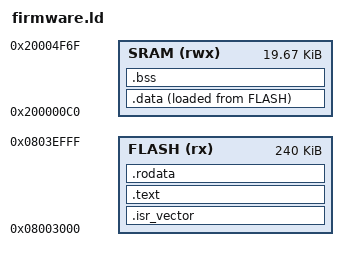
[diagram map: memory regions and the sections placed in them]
/* Linker Script definitivo: 256KB Flash e 20KB RAM oficial com Stack Pointer 0x20004F70 */

ENTRY(Reset_Handler)

MEMORY
{
  FLASH (rx)  : ORIGIN = 0x08003000, LENGTH = 240K
  SRAM  (rwx) : ORIGIN = 0x200000C0, LENGTH = 0x4EB0
}

_estack = 0x20004F70;

SECTIONS
{
  .isr_vector :
  {
    . = ALIGN(4);
    KEEP(*(.isr_vector))
    . = ALIGN(4);
  } >FLASH

  .text :
  {
    . = ALIGN(4);
    *(.text)
    *(.text*)
    *(.glue_7)
    *(.glue_7t)
    *(.eh_frame)
    KEEP(*(.init))
    KEEP(*(.fini))
    . = ALIGN(4);
    _etext = .;
  } >FLASH

  .rodata :
  {
    . = ALIGN(4);
    *(.rodata)
    *(.rodata*)
    . = ALIGN(4);
  } >FLASH

  .data :
  {
    . = ALIGN(4);
    _sdata = .;
    *(.data)
    *(.data*)
    . = ALIGN(4);
    _edata = .;
  } >SRAM AT>FLASH

  _sidata = LOADADDR(.data);

  .bss :
  {
    . = ALIGN(4);
    _sbss = .;
    *(.bss)
    *(.bss*)
    *(COMMON)
    . = ALIGN(4);
    _ebss = .;
    PROVIDE(end = .);
    PROVIDE(_end = .);
  } >SRAM

  /DISCARD/ :
  {
    libc.a (*)
    libm.a (*)
    libgcc.a (*)
  }
}
